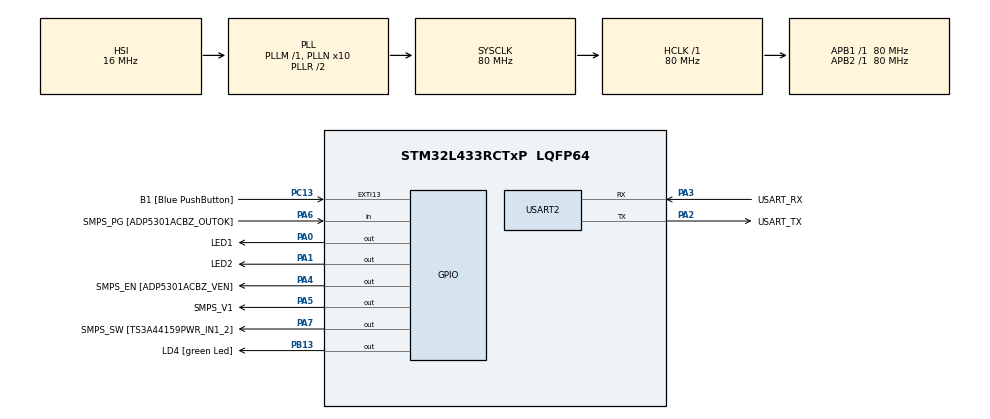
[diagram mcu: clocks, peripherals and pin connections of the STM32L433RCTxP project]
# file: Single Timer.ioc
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Mcu.Family=STM32L4
PA2.GPIO_PuPd=GPIO_NOPULL
RCC.CortexFreq_Value=80000000
NVIC.TIM6_DAC_IRQn=true\:0\:0\:false\:false\:true\:true\:true
PH0-OSC_IN\ (PH0).Signal=RCC_OSC_IN
PA3.GPIO_PuPd=GPIO_NOPULL
PA0.GPIO_Label=LED1
PA2.GPIO_Speed=GPIO_SPEED_FREQ_VERY_HIGH
PA6.GPIO_Label=SMPS_PG [ADP5301ACBZ_OUTOK]
PC15-OSC32_OUT\ (PC15).Mode=LSE-External-Oscillator
PC13.GPIO_Label=B1 [Blue PushButton]
PB13.GPIO_Label=LD4 [green Led]
PA3.GPIO_Speed=GPIO_SPEED_FREQ_VERY_HIGH
PB13.Signal=GPIO_Output
RCC.SYSCLKSource=RCC_SYSCLKSOURCE_PLLCLK
ProjectManager.StackSize=0x400
PB3\ (JTDO-TRACESWO).Signal=SYS_JTDO-SWO
PC14-OSC32_IN\ (PC14).Mode=LSE-External-Oscillator
PA14\ (JTCK-SWCLK).Signal=SYS_JTCK-SWCLK
RCC.HCLKFreq_Value=80000000
RCC.APB2TimFreq_Value=80000000
RCC.AHBFreq_Value=80000000
RCC.PREFETCH_ENABLE=1
RCC.HSE_VALUE=8000000
USART2.VirtualMode-Asynchronous=VM_ASYNC
PA6.GPIO_PuPd=GPIO_PULLUP
PA5.GPIO_PuPd=GPIO_NOPULL
PC13.GPIO_PuPd=GPIO_NOPULL
TIM6.Period=1999
PA0.Signal=GPIO_Output
Mcu.Package=LQFP64
PA6.Signal=GPIO_Input
PA2.GPIO_Label=USART_TX
RCC.APB1TimFreq_Value=80000000
PA13\ (JTMS-SWDIO).Signal=SYS_JTMS-SWDIO
PH0-OSC_IN\ (PH0).Mode=HSE-External-Clock-Source
PA4.GPIO_Label=SMPS_EN [ADP5301ACBZ_VEN]
RCC.HSI48_VALUE=48000000
PA3.Signal=USART2_RX
PA2.GPIO_Mode=GPIO_MODE_AF_PP
RCC.MSI_VALUE=4000000
RCC.PLLSourceVirtual=RCC_PLLSOURCE_HSI
PA14\ (JTCK-SWCLK).Mode=Serial_Wire
PC13.Signal=GPXTI13
TIM6.Prescaler=3999
VP_TIM6_VS_ClockSourceINT.Mode=Enable_Timer
PC15-OSC32_OUT\ (PC15).Signal=RCC_OSC32_OUT
PA14\ (JTCK-SWCLK).GPIO_Label=TCK
PB3\ (JTDO-TRACESWO).GPIO_Label=SWO
PH1-OSC_OUT\ (PH1).Signal=RCC_OSC_OUT
PA0.GPIO_Speed=GPIO_SPEED_FREQ_HIGH
PA3.Mode=Asynchronous
ProjectManager.TargetToolchain=STM32CubeIDE
PA3.GPIO_Mode=GPIO_MODE_AF_PP
RCC.USBFreq_Value=64000000
PA1.Signal=GPIO_Output
PA5.Signal=GPIO_Output
board=NUCLEO-L433RC-P
RCC.VCOOutputFreq_Value=160000000
RCC.APB2Freq_Value=80000000
PA5.GPIO_ModeDefaultOutputPP=GPIO_MODE_OUTPUT_PP
PA13\ (JTMS-SWDIO).GPIO_Label=TMS
PA1.GPIO_Speed=GPIO_SPEED_FREQ_HIGH
RCC.ADCFreq_Value=64000000
PA1.GPIO_Label=LED2
Mcu.Name=STM32L433RCTxP
PA2.Signal=USART2_TX
PA13\ (JTMS-SWDIO).Mode=Serial_Wire
PA4.Signal=GPIO_Output
RCC.SYSCLKFreq_VALUE=80000000
PA7.GPIO_Label=SMPS_SW [TS3A44159PWR_IN1_2]
PA5.GPIO_Label=SMPS_V1
PC13.GPIO_ModeDefaultEXTI=GPIO_MODE_IT_FALLING
PC14-OSC32_IN\ (PC14).Signal=RCC_OSC32_IN
ProjectManager.HeapSize=0x200
RCC.HSI_VALUE=16000000
PA5.GPIO_Speed=GPIO_SPEED_FREQ_LOW
NVIC.PriorityGroup=NVIC_PRIORITYGROUP_4
PH0-OSC_IN\ (PH0).GPIO_Label=MCO
RCC.PLLN=10
PA2.Mode=Asynchronous
RCC.APB1Freq_Value=80000000
PA3.GPIO_Label=USART_RX
PA7.Signal=GPIO_Output

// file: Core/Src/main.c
/* USER CODE BEGIN Header */
/**
  ******************************************************************************
  * @file           : main.c
  * @brief          : Main program body
  ******************************************************************************
  * @attention
  *
  * <h2><center>&copy; Copyright (c) 2022 STMicroelectronics.
  * All rights reserved.</center></h2>
  *
  * This software component is licensed by ST under BSD 3-Clause license,
  * the "License"; You may not use this file except in compliance with the
  * License. You may obtain a copy of the License at:
  *                        opensource.org/licenses/BSD-3-Clause
  *
  ******************************************************************************
  */
/* USER CODE END Header */
#include "main.h"

TIM_HandleTypeDef htim6;

UART_HandleTypeDef huart2;

void SystemClock_Config(void);
static void MX_GPIO_Init(void);
static void MX_USART2_UART_Init(void);
static void MX_TIM6_Init(void);

int main(void)
{

  HAL_Init();

  SystemClock_Config();

  MX_GPIO_Init();
  MX_USART2_UART_Init();
  MX_TIM6_Init();

  // Start timer
  HAL_TIM_Base_Start_IT(&htim6);

  // Callback: timer has rolled over
  // Callback: timer has rolled over
  void HAL_TIM_PeriodElapsedCallback(TIM_HandleTypeDef *htim);
  {
    // Check which version of the timer triggered this callback and toggle LED
    if (htim6 == TIM_HandleTypeDef *htim6)
    {
      HAL_GPIO_TogglePin(GPIOA, LED1_Pin);
    }
  }

  while (1)
  {

  }
  /* USER CODE END 3 */
}

void SystemClock_Config(void)
{
  RCC_OscInitTypeDef RCC_OscInitStruct = {0};
  RCC_ClkInitTypeDef RCC_ClkInitStruct = {0};
  RCC_PeriphCLKInitTypeDef PeriphClkInit = {0};

  /** Initializes the RCC Oscillators according to the specified parameters
  * in the RCC_OscInitTypeDef structure.
  */
  RCC_OscInitStruct.OscillatorType = RCC_OSCILLATORTYPE_HSI;
  RCC_OscInitStruct.HSIState = RCC_HSI_ON;
  RCC_OscInitStruct.HSICalibrationValue = RCC_HSICALIBRATION_DEFAULT;
  RCC_OscInitStruct.PLL.PLLState = RCC_PLL_ON;
  RCC_OscInitStruct.PLL.PLLSource = RCC_PLLSOURCE_HSI;
  RCC_OscInitStruct.PLL.PLLM = 1;
  RCC_OscInitStruct.PLL.PLLN = 10;
  RCC_OscInitStruct.PLL.PLLP = RCC_PLLP_DIV7;
  RCC_OscInitStruct.PLL.PLLQ = RCC_PLLQ_DIV2;
  RCC_OscInitStruct.PLL.PLLR = RCC_PLLR_DIV2;
  if (HAL_RCC_OscConfig(&RCC_OscInitStruct) != HAL_OK)
  {
    Error_Handler();
  }
  /** Initializes the CPU, AHB and APB buses clocks
  */
  RCC_ClkInitStruct.ClockType = RCC_CLOCKTYPE_HCLK|RCC_CLOCKTYPE_SYSCLK
                              |RCC_CLOCKTYPE_PCLK1|RCC_CLOCKTYPE_PCLK2;
  RCC_ClkInitStruct.SYSCLKSource = RCC_SYSCLKSOURCE_PLLCLK;
  RCC_ClkInitStruct.AHBCLKDivider = RCC_SYSCLK_DIV1;
  RCC_ClkInitStruct.APB1CLKDivider = RCC_HCLK_DIV1;
  RCC_ClkInitStruct.APB2CLKDivider = RCC_HCLK_DIV1;

  if (HAL_RCC_ClockConfig(&RCC_ClkInitStruct, FLASH_LATENCY_4) != HAL_OK)
  {
    Error_Handler();
  }
  PeriphClkInit.PeriphClockSelection = RCC_PERIPHCLK_USART2;
  PeriphClkInit.Usart2ClockSelection = RCC_USART2CLKSOURCE_PCLK1;
  if (HAL_RCCEx_PeriphCLKConfig(&PeriphClkInit) != HAL_OK)
  {
    Error_Handler();
  }
  /** Configure the main internal regulator output voltage
  */
  if (HAL_PWREx_ControlVoltageScaling(PWR_REGULATOR_VOLTAGE_SCALE1) != HAL_OK)
  {
    Error_Handler();
  }
}

static void MX_TIM6_Init(void)
{

  TIM_MasterConfigTypeDef sMasterConfig = {0};

  htim6.Instance = TIM6;
  htim6.Init.Prescaler = 3999;
  htim6.Init.CounterMode = TIM_COUNTERMODE_UP;
  htim6.Init.Period = 1999;
  htim6.Init.AutoReloadPreload = TIM_AUTORELOAD_PRELOAD_DISABLE;
  if (HAL_TIM_Base_Init(&htim6) != HAL_OK)
  {
    Error_Handler();
  }
  sMasterConfig.MasterOutputTrigger = TIM_TRGO_RESET;
  sMasterConfig.MasterSlaveMode = TIM_MASTERSLAVEMODE_DISABLE;
  if (HAL_TIMEx_MasterConfigSynchronization(&htim6, &sMasterConfig) != HAL_OK)
  {
    Error_Handler();
  }

}

static void MX_USART2_UART_Init(void)
{

  huart2.Instance = USART2;
  huart2.Init.BaudRate = 115200;
  huart2.Init.WordLength = UART_WORDLENGTH_8B;
  huart2.Init.StopBits = UART_STOPBITS_1;
  huart2.Init.Parity = UART_PARITY_NONE;
  huart2.Init.Mode = UART_MODE_TX_RX;
  huart2.Init.HwFlowCtl = UART_HWCONTROL_NONE;
  huart2.Init.OverSampling = UART_OVERSAMPLING_16;
  huart2.Init.OneBitSampling = UART_ONE_BIT_SAMPLE_DISABLE;
  huart2.AdvancedInit.AdvFeatureInit = UART_ADVFEATURE_NO_INIT;
  if (HAL_UART_Init(&huart2) != HAL_OK)
  {
    Error_Handler();
  }

}

static void MX_GPIO_Init(void)
{
  GPIO_InitTypeDef GPIO_InitStruct = {0};

  /* GPIO Ports Clock Enable */
  __HAL_RCC_GPIOC_CLK_ENABLE();
  __HAL_RCC_GPIOH_CLK_ENABLE();
  __HAL_RCC_GPIOA_CLK_ENABLE();
  __HAL_RCC_GPIOB_CLK_ENABLE();

  /*Configure GPIO pin Output Level */
  HAL_GPIO_WritePin(GPIOA, LED1_Pin|LED2_Pin|SMPS_EN_Pin|SMPS_V1_Pin
                          |SMPS_SW_Pin, GPIO_PIN_RESET);

  /*Configure GPIO pin Output Level */
  HAL_GPIO_WritePin(LD4_GPIO_Port, LD4_Pin, GPIO_PIN_RESET);

  /*Configure GPIO pin : B1_Pin */
  GPIO_InitStruct.Pin = B1_Pin;
  GPIO_InitStruct.Mode = GPIO_MODE_IT_FALLING;
  GPIO_InitStruct.Pull = GPIO_NOPULL;
  HAL_GPIO_Init(B1_GPIO_Port, &GPIO_InitStruct);

  /*Configure GPIO pins : LED1_Pin LED2_Pin */
  GPIO_InitStruct.Pin = LED1_Pin|LED2_Pin;
  GPIO_InitStruct.Mode = GPIO_MODE_OUTPUT_PP;
  GPIO_InitStruct.Pull = GPIO_NOPULL;
  GPIO_InitStruct.Speed = GPIO_SPEED_FREQ_HIGH;
  HAL_GPIO_Init(GPIOA, &GPIO_InitStruct);

  /*Configure GPIO pins : SMPS_EN_Pin SMPS_V1_Pin SMPS_SW_Pin */
  GPIO_InitStruct.Pin = SMPS_EN_Pin|SMPS_V1_Pin|SMPS_SW_Pin;
  GPIO_InitStruct.Mode = GPIO_MODE_OUTPUT_PP;
  GPIO_InitStruct.Pull = GPIO_NOPULL;
  GPIO_InitStruct.Speed = GPIO_SPEED_FREQ_LOW;
  HAL_GPIO_Init(GPIOA, &GPIO_InitStruct);

  /*Configure GPIO pin : SMPS_PG_Pin */
  GPIO_InitStruct.Pin = SMPS_PG_Pin;
  GPIO_InitStruct.Mode = GPIO_MODE_INPUT;
  GPIO_InitStruct.Pull = GPIO_PULLUP;
  HAL_GPIO_Init(SMPS_PG_GPIO_Port, &GPIO_InitStruct);

  /*Configure GPIO pin : LD4_Pin */
  GPIO_InitStruct.Pin = LD4_Pin;
  GPIO_InitStruct.Mode = GPIO_MODE_OUTPUT_PP;
  GPIO_InitStruct.Pull = GPIO_NOPULL;
  GPIO_InitStruct.Speed = GPIO_SPEED_FREQ_LOW;
  HAL_GPIO_Init(LD4_GPIO_Port, &GPIO_InitStruct);

}

/* USER CODE BEGIN 4 */

//void HAL_TIM_PeriodElapsedCallback(TIM_HandleTypeDef *htim)
//{
//	HAL_GPIO_TogglePin(GPIOA, LED1_Pin);
//}
/* USER CODE END 4 */

void Error_Handler(void)
{
  __disable_irq();
  while (1)
  {
  }
}

/************************ (C) COPYRIGHT STMicroelectronics *****END OF FILE****/
